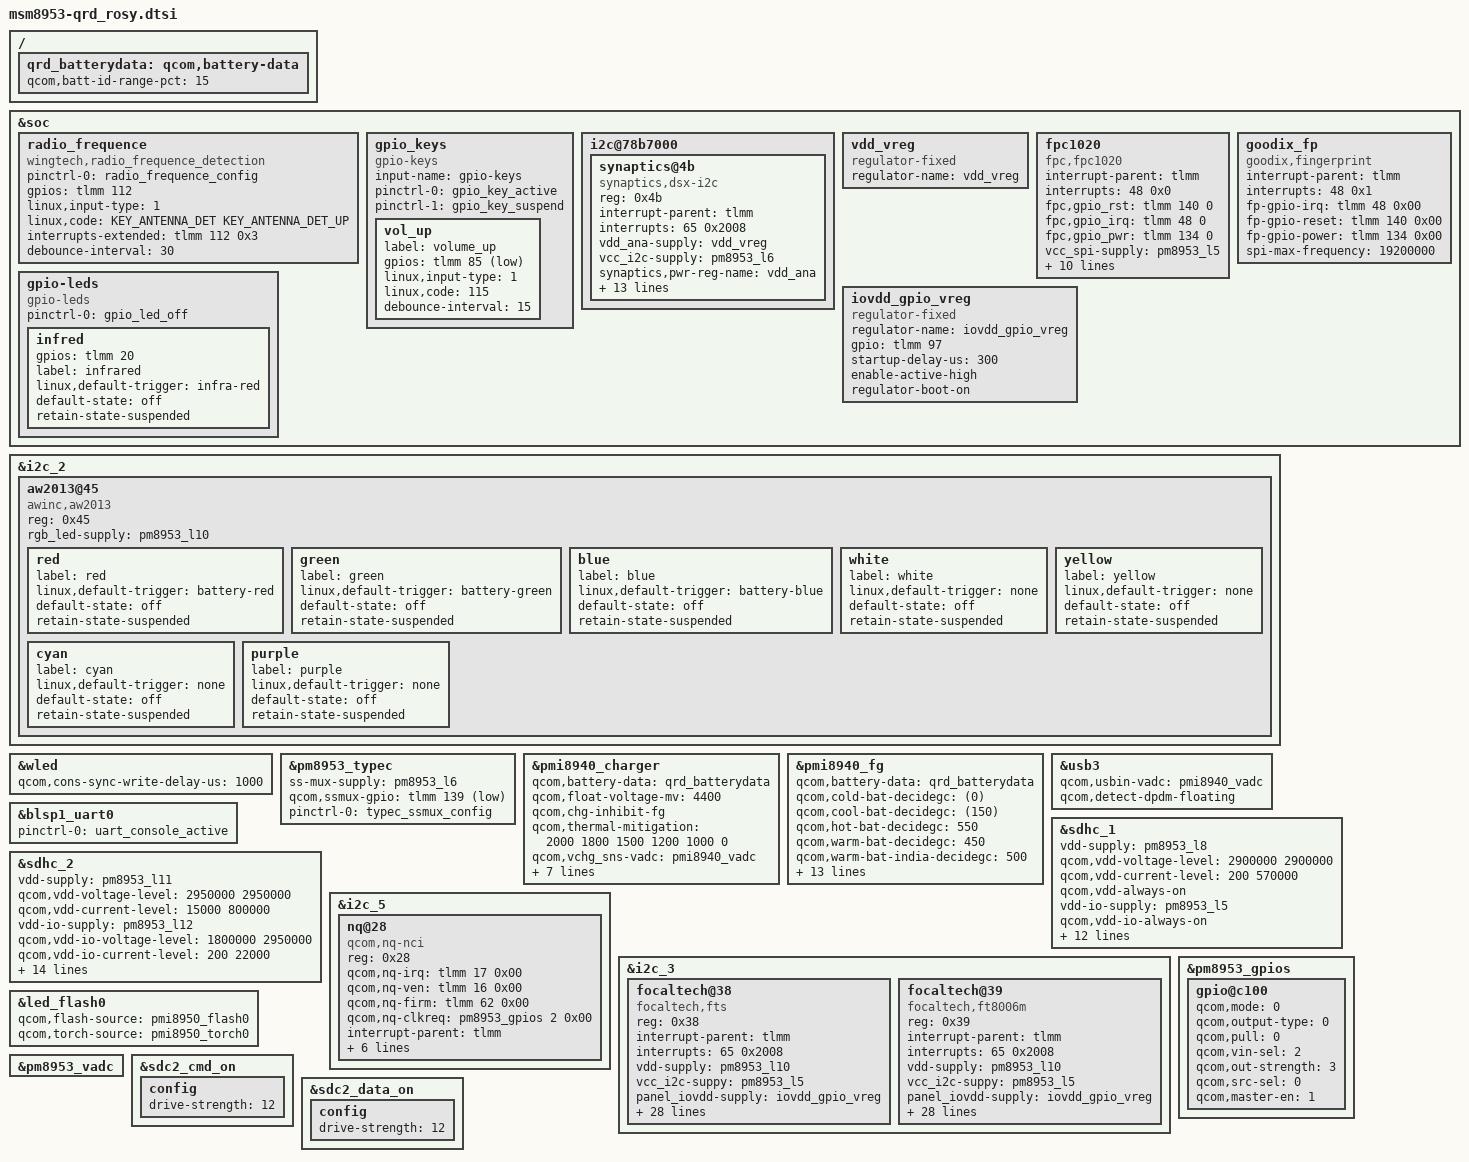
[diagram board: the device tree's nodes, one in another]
/*
 * Copyright (c) 2015-2016, The Linux Foundation. All rights reserved.
 * Copyright (C) 2018 XiaoMi, Inc.
 *
 * This program is free software; you can redistribute it and/or modify
 * it under the terms of the GNU General Public License version 2 and
 * only version 2 as published by the Free Software Foundation.
 *
 * This program is distributed in the hope that it will be useful,
 * but WITHOUT ANY WARRANTY; without even the implied warranty of
 * MERCHANTABILITY or FITNESS FOR A PARTICULAR PURPOSE.  See the
 * GNU General Public License for more details.
 */

#include "msm8953-pinctrl_rosy.dtsi"
#include "msm8953-camera-sensor-qrd_rosy.dtsi"
#include <dt-bindings/input/input.h>
#include <dt-bindings/gpio/gpio.h>

&soc {
	radio_frequence {
		compatible = "wingtech,radio_frequence_detection";
		pinctrl-names = "default";
		pinctrl-0 = <&radio_frequence_config>;
		gpios = <&tlmm 112 GPIO_ACTIVE_HIGH>;
		linux,input-type = <1>;
		linux,code = <KEY_ANTENNA_DET KEY_ANTENNA_DET_UP>;
		interrupts-extended = <&tlmm 112 0x3>;
		debounce-interval = <30>;
	};

	gpio_keys {
		compatible = "gpio-keys";
		input-name = "gpio-keys";
		pinctrl-names = "tlmm_gpio_key_active","tlmm_gpio_key_suspend";
		pinctrl-0 = <&gpio_key_active>;
		pinctrl-1 = <&gpio_key_suspend>;

		vol_up {
			label = "volume_up";
			gpios = <&tlmm 85 0x1>;
			linux,input-type = <1>;
			linux,code = <115>;
			debounce-interval = <15>;
		};
	};

	i2c@78b7000 { /* BLSP1 QUP3 */
		status = "okay";
		synaptics@4b {
			compatible = "synaptics,dsx-i2c";
			reg = <0x4b>;
			interrupt-parent = <&tlmm>;
			interrupts = <65 0x2008>;
			vdd_ana-supply = <&vdd_vreg>;
			vcc_i2c-supply = <&pm8953_l6>;
			synaptics,pwr-reg-name = "vdd_ana";
			synaptics,bus-reg-name = "vcc_i2c";
			synaptics,irq-gpio = <&tlmm 65 0x2008>;
			synaptics,irq-on-state = <0>;
			synaptics,irq-flags = <0x2008>;
			synaptics,power-delay-ms = <200>;
			synaptics,reset-delay-ms = <200>;
			synaptics,max-y-for-2d = <1919>;
			synaptics,cap-button-codes = <139 158 172>;
			synaptics,vir-button-codes = <139 180 2000 320 160
					158 540 2000 320 160
					172 900 2000 320 160>;
			synaptics,resume-in-workqueue;
			/* Underlying clocks used by secure touch */
			clock-names = "iface_clk", "core_clk";
			clocks = <&clock_gcc clk_gcc_blsp1_ahb_clk>,
				<&clock_gcc clk_gcc_blsp1_qup3_i2c_apps_clk>;
		};
	};

	vdd_vreg: vdd_vreg {
		compatible = "regulator-fixed";
		status = "ok";
		regulator-name = "vdd_vreg";
	};
	fpc1020 {
		compatible = "fpc,fpc1020";

		interrupt-parent = <&tlmm>;
		interrupts = <48 0x0>;

		fpc,gpio_rst    = <&tlmm 140 0>;
		fpc,gpio_irq    = <&tlmm 48 0>;
		fpc,gpio_pwr   = <&tlmm 134 0>;

		vcc_spi-supply  = <&pm8953_l5>;
		vdd_ana-supply  = <&pm8953_l5>;
		vdd_io-supply   = <&pm8953_l5>;

		fpc,enable-on-boot;
		/delete-property/
		fpc,enable-wakeup;

		fpc,spi-max-frequency = <4800000>;

		/* Only for SPI Clock Handled by Linux */
		clock-names = "iface_clk", "core_clk";
		clocks = <&clock_gcc clk_gcc_blsp1_ahb_clk>,
			<&clock_gcc clk_gcc_blsp1_qup1_spi_apps_clk>;

		pinctrl-names = "fpc1020_spi_active",
				"fpc1020_reset_reset",
				"fpc1020_reset_active",
				"fpc1020_irq_active";

		pinctrl-0 = <&fpc_spi_active>;
		pinctrl-1 = <&fpc_reset_reset>;
		pinctrl-2 = <&fpc_reset_active>;
		pinctrl-3 = <&fpc_irq_active>;
	};

	goodix_fp {
		compatible = "goodix,fingerprint";
		interrupt-parent = <&tlmm>;
		interrupts = <48 0x1>;
		fp-gpio-irq = <&tlmm 48 0x00>;
		fp-gpio-reset = <&tlmm 140 0x00>;
		fp-gpio-power = <&tlmm 134 0x00>;
		spi-max-frequency = <19200000>;
	};
	gpio-leds {
		compatible = "gpio-leds";
		status = "okay";
		pinctrl-names = "default";
		pinctrl-0 = <&gpio_led_off>;

			infred {
			gpios = <&tlmm 20 0>;
			label = "infrared";
			linux,default-trigger = "infra-red";
			default-state = "off";
			retain-state-suspended;
		};

	};

	iovdd_gpio_vreg: iovdd_gpio_vreg {
		compatible = "regulator-fixed";
		regulator-name="iovdd_gpio_vreg";
		gpio = <&tlmm 97 0>; /* iovdd - ldo6 */
		startup-delay-us = <300>;
		enable-active-high;
		regulator-boot-on;
		status = "ok";
	};

};
&i2c_2 { /* i2c 2 */
		aw2013@45 { /*blink */
		compatible = "awinc,aw2013";
		reg = <0x45>;
		rgb_led-supply = <&pm8953_l10>;

		red {
			label = "red";
			linux,default-trigger = "battery-red";
			default-state = "off";
			retain-state-suspended;
		};

		green {
			label = "green";
			linux,default-trigger = "battery-green";
			default-state = "off";
			retain-state-suspended;
		};

		blue {
			label = "blue";
			linux,default-trigger = "battery-blue";
			default-state = "off";
			retain-state-suspended;
		};
		white {
			label = "white";
			linux,default-trigger = "none";
			default-state = "off";
			retain-state-suspended;
		};

		yellow {
			label = "yellow";
			linux,default-trigger = "none";
			default-state = "off";
			retain-state-suspended;
		};

		cyan {
			label = "cyan";
			linux,default-trigger = "none";
			default-state = "off";
			retain-state-suspended;
		};
		purple {
			label = "purple";
			linux,default-trigger = "none";
			default-state = "off";
			retain-state-suspended;
		};
		};
	};
&wled {
	qcom,cons-sync-write-delay-us = <1000>;
};

/ {
	qrd_batterydata: qcom,battery-data {
		qcom,batt-id-range-pct = <15>;
		#include "batterydata-Scud-4v4-3300mah.dtsi"
		#include "batterydata-Sunwoda-4v4-3300mah.dtsi"
		#include "batterydata-D1_Default-4v4-3300mah.dtsi"
	};
};

&pm8953_typec {
	ss-mux-supply = <&pm8953_l6>;
	qcom,ssmux-gpio = <&tlmm 139 GPIO_ACTIVE_LOW>;
	pinctrl-names = "default";
	pinctrl-0 = <&typec_ssmux_config>;
};

&pmi8940_charger {
	qcom,battery-data = <&qrd_batterydata>;
	qcom,float-voltage-mv = <4400>;
	qcom,chg-inhibit-fg;
	qcom,thermal-mitigation = <2000 1800 1500 1200 1000 0>;
	status = "okay";
	qcom,vchg_sns-vadc = <&pmi8940_vadc>;
	qcom,vchg-adc-channel-id = <3>;
	qcom,customize-cool-low-limit = <0>;
	qcom,customize-cool-high-limit = <50>;
	qcom,fastchg-current-customize-cool = <300>;
	qcom,fastchg-current-bat-cool = <900>;
	qcom,fastchg-current-ma = <2000>;
	qcom,override-usb-current;
};

&pmi8940_fg {
	qcom,battery-data = <&qrd_batterydata>;
	qcom,cold-bat-decidegc = <(0)>;
	qcom,cool-bat-decidegc = <(150)>;
	qcom,hot-bat-decidegc = <550>;
	qcom,warm-bat-decidegc = <450>;
	qcom,warm-bat-india-decidegc = <500>;
	qcom,fg-iterm-ma = <230>;
	qcom,fg-chg-iterm-ma = <200>;
	qcom,resume-soc = <99>;
	qcom,resume-soc-raw = <253>;
	qcom,vbat-estimate-diff-mv = <100>;
	qcom,fg-cutoff-voltage-mv = <3400>;
	qcom,fg-cc-cv-threshold-mv = <4390>;
	qcom,cl-max-increment-deciperc = <1>;
	qcom,cl-max-decrement-deciperc = <1>;
	qcom,fg-delta-soc = <2>;
	qcom,bad-battery-detection-enable;
	qcom,hold-soc-while-full;
	qcom,thermal-coefficients = [DA 86 F0 50 08 3C];
};

&usb3 {
	qcom,usbin-vadc = <&pmi8940_vadc>;
	qcom,detect-dpdm-floating;
};

&blsp1_uart0 {
	status = "ok";
	pinctrl-names = "default";
	pinctrl-0 = <&uart_console_active>;
};

&sdhc_1 {
	/* device core power supply */
	vdd-supply = <&pm8953_l8>;
	qcom,vdd-voltage-level = <2900000 2900000>;
	qcom,vdd-current-level = <200 570000>;
	qcom,vdd-always-on;

	/* device communication power supply */
	vdd-io-supply = <&pm8953_l5>;
	qcom,vdd-io-always-on;
	qcom,vdd-io-lpm-sup;
	qcom,vdd-io-voltage-level = <1800000 1800000>;
	qcom,vdd-io-current-level = <200 325000>;

	pinctrl-names = "active", "sleep";
	pinctrl-0 = <&sdc1_clk_on &sdc1_cmd_on &sdc1_data_on &sdc1_rclk_on>;
	pinctrl-1 = <&sdc1_clk_off &sdc1_cmd_off &sdc1_data_off &sdc1_rclk_off>;

	qcom,clk-rates = <400000 20000000 25000000 50000000 100000000 192000000
								384000000>;
	qcom,nonremovable;
	qcom,bus-speed-mode = "HS400_1p8v", "HS200_1p8v", "DDR_1p8v";

	status = "ok";
};

&sdhc_2 {
	/* device core power supply */
	vdd-supply = <&pm8953_l11>;
	qcom,vdd-voltage-level = <2950000 2950000>;
	qcom,vdd-current-level = <15000 800000>;

	/* device communication power supply */
	vdd-io-supply = <&pm8953_l12>;
	qcom,vdd-io-voltage-level = <1800000 2950000>;
	qcom,vdd-io-current-level = <200 22000>;

	pinctrl-names = "active", "sleep";
	pinctrl-0 = <&sdc2_clk_on &sdc2_cmd_on &sdc2_data_on &sdc2_cd_on>;
	pinctrl-1 = <&sdc2_clk_off &sdc2_cmd_off &sdc2_data_off &sdc2_cd_off>;

	#address-cells = <0>;
	interrupt-parent = <&sdhc_2>;
	interrupts = <0 1 2>;
	#interrupt-cells = <1>;
	interrupt-map-mask = <0xffffffff>;
	interrupt-map = <0 &intc 0 125 0
		1 &intc 0 221 0
		2 &tlmm 133 0>;
	interrupt-names = "hc_irq", "pwr_irq", "status_irq";
	cd-gpios = <&tlmm 133 0x0>;

	qcom,clk-rates = <400000 20000000 25000000 50000000 100000000
								200000000>;
	qcom,bus-speed-mode = "SDR12", "SDR25", "SDR50", "DDR50", "SDR104";

	status = "ok";
};

&i2c_5 { /* BLSP2 QUP1 (NFC) */
	nq@28 {
		compatible = "qcom,nq-nci";
		reg = <0x28>;
		qcom,nq-irq = <&tlmm 17 0x00>;
		qcom,nq-ven = <&tlmm 16 0x00>;
		qcom,nq-firm = <&tlmm 62 0x00>;
		qcom,nq-clkreq = <&pm8953_gpios 2 0x00>;
		interrupt-parent = <&tlmm>;
		qcom,clk-src = "BBCLK2";
		interrupts = <17 0>;
		interrupt-names = "nfc_irq";
		pinctrl-names = "nfc_active", "nfc_suspend";
		pinctrl-0 = <&nfc_int_active &nfc_disable_active>;
		pinctrl-1 = <&nfc_int_suspend &nfc_disable_suspend>;
		clocks = <&clock_gcc clk_bb_clk2_pin>;
		clock-names = "ref_clk";
	};
};

&i2c_3 {
	status = "ok";
	focaltech@38{
		compatible = "focaltech,fts";
		reg = <0x38>;
		interrupt-parent = <&tlmm>;
		interrupts = <65 0x2008>;
		vdd-supply = <&pm8953_l10>;
		vcc_i2c-suppy = <&pm8953_l5>;
		panel_iovdd-supply = <&iovdd_gpio_vreg>;
		lab-supply = <&lab_regulator>;
		ibb-supply = <&ibb_regulator>;
		/* pins used by touchscreen */
		pinctrl-names = "pmx_ts_active","pmx_ts_suspend",
			"pmx_ts_release";
		pinctrl-0 = <&ts_int_active &ts_reset_active>;
		pinctrl-1 = <&ts_int_suspend &ts_reset_suspend>;
		pinctrl-2 = <&ts_release>;
		focaltech,name = "fts_ts";
		focaltech,family-id = <0x54>;
		focaltech,reset-gpio = <&tlmm 64 0x00>;
		focaltech,irq-gpio = <&tlmm 65 0x2008>;
		focaltech,display-coords = <0 0 720 1440>;
		focaltech,panel-coords = <0 0 720 1440>;
		/*ftech,button-map= <139 102 158>;*/
		focaltech,virtual-key1 = <139 560 2000>;/*menu*/
		focaltech,virtual-key2 = <102 360 2000>;/*home*/
		focaltech,virtual-key3 = <158 160 2000>;/*back*/
		focaltech,no-force-update;
		focaltech,i2c-pull-up;
		focaltech,group-id = <1>;
		focaltech,hard-reset-delay-ms = <20>;
		focaltech,soft-reset-delay-ms = <200>;
		focaltech,num-max-touches = <10>;
		focaltech,fw-delay-aa-ms = <30>;
		focaltech,fw-delay-55-ms = <30>;
		focaltech,fw-upgrade-id1 = <0x79>;
		focaltech,fw-upgrade-id2 = <0x18>;
		focaltech,fw-delay-readid-ms = <10>;
		focaltech,fw-delay-era-flsh-ms = <2000>;
		focaltech,fw-auto-cal;
		focaltech,ignore-id-check;
	};
	focaltech@39{
		compatible = "focaltech,ft8006m";
		reg = <0x39>;
		interrupt-parent = <&tlmm>;
		interrupts = <65 0x2008>;
		vdd-supply = <&pm8953_l10>;
		vcc_i2c-suppy = <&pm8953_l5>;
		panel_iovdd-supply = <&iovdd_gpio_vreg>;
		lab-supply = <&lab_regulator>;
		ibb-supply = <&ibb_regulator>;
		/* pins used by touchscreen */
		pinctrl-names = "pmx_ts_active","pmx_ts_suspend",
			"pmx_ts_release";
		pinctrl-0 = <&ts_int_active &ts_reset_active>;
		pinctrl-1 = <&ts_int_suspend &ts_reset_suspend>;
		pinctrl-2 = <&ts_release>;
		focaltech,name = "fts_ts";
		focaltech,family-id = <0x54>;
		focaltech,reset-gpio = <&tlmm 64 0x00>;
		focaltech,irq-gpio = <&tlmm 65 0x2008>;
		focaltech,display-coords = <0 0 720 1440>;
		focaltech,panel-coords = <0 0 720 1440>;
		focaltech,virtual-key1 = <139 560 2000>;/*menu*/
		focaltech,virtual-key2 = <102 360 2000>;/*home*/
		focaltech,virtual-key3 = <158 160 2000>;/*back*/
		focaltech,no-force-update;
		focaltech,i2c-pull-up;
		focaltech,group-id = <1>;
		focaltech,hard-reset-delay-ms = <20>;
		focaltech,soft-reset-delay-ms = <200>;
		focaltech,num-max-touches = <10>;
		focaltech,fw-delay-aa-ms = <30>;
		focaltech,fw-delay-55-ms = <30>;
		focaltech,fw-upgrade-id1 = <0x79>;
		focaltech,fw-upgrade-id2 = <0x18>;
		focaltech,fw-delay-readid-ms = <10>;
		focaltech,fw-delay-era-flsh-ms = <2000>;
		focaltech,fw-auto-cal;
		focaltech,ignore-id-check;
	};

};

&pm8953_gpios {
	/* GPIO 2 (NFC_CLK_REQ) */
	gpio@c100 {
		qcom,mode = <0>;
		qcom,output-type = <0>;
		qcom,pull = <0>;
		qcom,vin-sel = <2>;
		qcom,out-strength = <3>;
		qcom,src-sel = <0>;
		qcom,master-en = <1>;
		status = "okay";
	};
};

&i2c_3 {
	status = "ok";
};

&led_flash0{
	qcom,flash-source = <&pmi8950_flash0>;
	qcom,torch-source = <&pmi8950_torch0>;
};

&pm8953_vadc {
	/delete-node/ chan@11;
};

&sdc2_cmd_on {
	config {
		drive-strength=<12>;
	};
};

&sdc2_data_on {
	config {
		drive-strength=<12>;
	};
};
